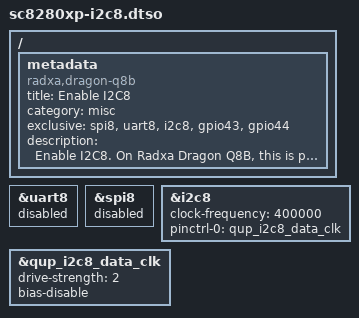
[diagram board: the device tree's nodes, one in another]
// SPDX-License-Identifier: BSD-3-Clause
/*
 * Copyright (c) 2026 Radxa Computer (Shenzhen) Co., Ltd.
 */

/dts-v1/;
/plugin/;

/ {
	metadata {
		title = "Enable I2C8";
		compatible = "radxa,dragon-q8b";
		category = "misc";
		exclusive = "spi8", "uart8", "i2c8", "gpio43", "gpio44";
		description = "Enable I2C8.
On Radxa Dragon Q8B, this is pin 27(scl), 28(sda).";
	};
};

&uart8 {
	status = "disabled";
};

&spi8 {
	status = "disabled";
};

&i2c8 {
	clock-frequency = <400000>;

	pinctrl-0 = <&qup_i2c8_data_clk>;
	pinctrl-names = "default";

	status = "okay";
};

&qup_i2c8_data_clk {
	drive-strength = <2>;
	bias-disable;
};
